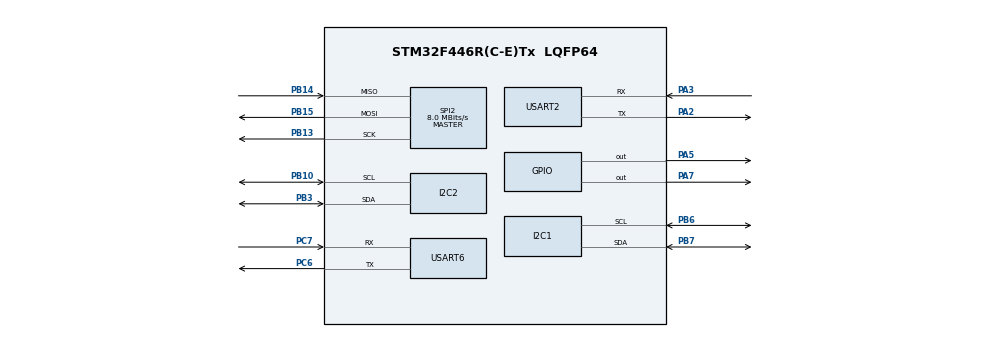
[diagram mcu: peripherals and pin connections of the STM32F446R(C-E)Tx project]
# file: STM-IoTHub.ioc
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FREERTOS.Tasks01=defaultTask,24,128,StartDefaultTask,Default,NULL,Dynamic,NULL,NULL;SensorTask,24,256,StartSensorTask,Default,NULL,Dynamic,NULL,NULL;DisplayTask,8,256,StartDisplayTask,Default,NULL,Dynamic,NULL,NULL;WiFiTask,24,256,StartWiFiTask,Default,NULL,Dynamic,NULL,NULL;RelayTask,40,256,StartRelayControlTask,Default,NULL,Dynamic,NULL,NULL;EnergyTask,24,256,StartEnergyTask,Default,NULL,Dynamic,NULL,NULL;SDLogTask,8,256,StartSDLogTask,Default,NULL,Dynamic,NULL,NULL;SystemStatusTas,8,256,StartSystemStatusTask,Default,NULL,Dynamic,NULL,NULL
Mcu.Family=STM32F4
Mcu.Name=STM32F446R(C-E)Tx
Mcu.Package=LQFP64
NVIC.PriorityGroup=NVIC_PRIORITYGROUP_4
PA2.Mode=Asynchronous
PA2.Signal=USART2_TX
PA3.Mode=Asynchronous
PA3.Signal=USART2_RX
PA5.Signal=GPIO_Output
PA7.Signal=GPIO_Output
PB10.Mode=I2C
PB10.Signal=I2C2_SCL
PB13.Mode=Full_Duplex_Master
PB13.Signal=SPI2_SCK
PB14.Mode=Full_Duplex_Master
PB14.Signal=SPI2_MISO
PB15.Mode=Full_Duplex_Master
PB15.Signal=SPI2_MOSI
PB3.Mode=I2C
PB3.Signal=I2C2_SDA
PB6.Mode=I2C
PB6.Signal=I2C1_SCL
PB7.Mode=I2C
PB7.Signal=I2C1_SDA
PC6.Mode=Asynchronous
PC6.Signal=USART6_TX
PC7.Mode=Asynchronous
PC7.Signal=USART6_RX
ProjectManager.HeapSize=0x200
ProjectManager.StackSize=0x400
ProjectManager.TargetToolchain=STM32CubeIDE
RCC.CortexFreq_Value=16000000
RCC.USBFreq_Value=96000000
RCC.VCOOutputFreq_Value=192000000
SPI2.CalculateBaudRate=8.0 MBits/s
SPI2.Direction=SPI_DIRECTION_2LINES
SPI2.Mode=SPI_MODE_MASTER
SPI2.VirtualType=VM_MASTER
USART2.VirtualMode=VM_ASYNC
USART6.VirtualMode=VM_ASYNC
VP_FATFS_VS_Generic.Mode=User_defined
VP_FREERTOS_VS_CMSIS_V2.Mode=CMSIS_V2
VP_RTC_VS_RTC_Activate.Mode=RTC_Enabled
VP_RTC_VS_RTC_Calendar.Mode=RTC_Calendar
board=custom

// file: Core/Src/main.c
/* USER CODE BEGIN Header */
/**
  ******************************************************************************
  * @file           : main.c
  * @brief          : Main program body
  ******************************************************************************
  * @attention
  *
  * Copyright (c) 2025 STMicroelectronics.
  * All rights reserved.
  *
  * This software is licensed under terms that can be found in the LICENSE file
  * in the root directory of this software component.
  * If no LICENSE file comes with this software, it is provided AS-IS.
  *
  ******************************************************************************
  */
/* USER CODE END Header */

#include "main.h"
#include "cmsis_os.h"
#include "bme68x.h"
#include "bme680_app.h"
#include "ssd1306.h"
#include "relay_control.h"
#include "pzem004t.h"
#include "esp8266.h"
#include "fatfs.h"
#include "fatfs_sd.h"

/* USER CODE BEGIN Includes */
struct bme68x_dev bme;              // Sensor device structure
struct bme68x_conf conf;            // Configuration
struct bme68x_heatr_conf heatr_conf;
extern void StartSensorTask(void *argument);
extern UART_HandleTypeDef huart2;
extern UART_HandleTypeDef huart2;
extern volatile uint8_t user_light_state;
extern osThreadId_t fanTaskHandle;
// Heater config
/* USER CODE END Includes */

I2C_HandleTypeDef hi2c1;
I2C_HandleTypeDef hi2c2;

RTC_HandleTypeDef hrtc;

SPI_HandleTypeDef hspi2;

UART_HandleTypeDef huart2;
UART_HandleTypeDef huart6;

/* Definitions for defaultTask */
osThreadId_t defaultTaskHandle;
const osThreadAttr_t defaultTask_attributes = {
  .name = "defaultTask",
  .stack_size = 128 * 4,
  .priority = (osPriority_t) osPriorityNormal,
};
/* Definitions for SensorTask */
osThreadId_t SensorTaskHandle;
const osThreadAttr_t SensorTask_attributes = {
  .name = "SensorTask",
  .stack_size = 256 * 4,
  .priority = (osPriority_t) osPriorityNormal,
};
/* Definitions for DisplayTask */
osThreadId_t DisplayTaskHandle;
const osThreadAttr_t DisplayTask_attributes = {
  .name = "DisplayTask",
  .stack_size = 256 * 4,
  .priority = (osPriority_t) osPriorityLow,
};
/* Definitions for WiFiTask */
osThreadId_t WiFiTaskHandle;
const osThreadAttr_t WiFiTask_attributes = {
  .name = "WiFiTask",
  .stack_size = 256 * 4,
  .priority = (osPriority_t) osPriorityNormal,
};
/* Definitions for RelayTask */
osThreadId_t RelayTaskHandle;
const osThreadAttr_t RelayTask_attributes = {
  .name = "RelayTask",
  .stack_size = 256 * 4,
  .priority = (osPriority_t) osPriorityHigh,
};
/* Definitions for EnergyTask */
osThreadId_t EnergyTaskHandle;
const osThreadAttr_t EnergyTask_attributes = {
  .name = "EnergyTask",
  .stack_size = 256 * 4,
  .priority = (osPriority_t) osPriorityNormal,
};
/* Definitions for SDLogTask */
osThreadId_t SDLogTaskHandle;
const osThreadAttr_t SDLogTask_attributes = {
  .name = "SDLogTask",
  .stack_size = 256 * 4,
  .priority = (osPriority_t) osPriorityLow,
};
/* Definitions for SystemStatusTas */
osThreadId_t SystemStatusTasHandle;
const osThreadAttr_t SystemStatusTas_attributes = {
  .name = "SystemStatusTas",
  .stack_size = 256 * 4,
  .priority = (osPriority_t) osPriorityLow,
};

void SystemClock_Config(void);
static void MX_GPIO_Init(void);
static void MX_I2C2_Init(void);
static void MX_USART2_UART_Init(void);
static void MX_RTC_Init(void);
static void MX_I2C1_Init(void);
static void MX_SPI2_Init(void);
static void MX_USART6_UART_Init(void);
void StartDefaultTask(void *argument);
void StartSensorTask(void *argument);
void StartDisplayTask(void *argument);
void StartWiFiTask(void *argument);
void StartRelayControlTask(void *argument);
void StartEnergyTask(void *argument);
void StartSDLogTask(void *argument);
void StartSystemStatusTask(void *argument);

int main(void)
{

  /* MCU Configuration--------------------------------------------------------*/

  /* Reset of all peripherals, Initializes the Flash interface and the Systick. */
  HAL_Init();

  /* Configure the system clock */
  SystemClock_Config();

  /* USER CODE BEGIN SysInit */
  BME680_Init();          // Initialize BME680 sensor
  SSD1306_Init();         // Initialize OLED Display
  Relay_Init();           // Initialize Relay GPIOs
  PZEM_Init(&huart2);
  ESP_Init(&huart2);
  /* USER CODE END SysInit */

  /* Initialize all configured peripherals */
  MX_GPIO_Init();
  MX_I2C2_Init();
  MX_USART2_UART_Init();
  MX_FATFS_Init();
  MX_RTC_Init();
  MX_I2C1_Init();
  MX_SPI2_Init();
  MX_USART6_UART_Init();

  /* Init scheduler */
  osKernelInitialize();

  /* Create the thread(s) */
  /* creation of defaultTask */
  defaultTaskHandle = osThreadNew(StartDefaultTask, NULL, &defaultTask_attributes);

  /* creation of SensorTask */
  SensorTaskHandle = osThreadNew(StartSensorTask, NULL, &SensorTask_attributes);

  /* creation of DisplayTask */
  DisplayTaskHandle = osThreadNew(StartDisplayTask, NULL, &DisplayTask_attributes);

  /* creation of WiFiTask */
  WiFiTaskHandle = osThreadNew(StartWiFiTask, NULL, &WiFiTask_attributes);

  /* creation of RelayTask */
  RelayTaskHandle = osThreadNew(StartRelayControlTask, NULL, &RelayTask_attributes);

  /* creation of EnergyTask */
  EnergyTaskHandle = osThreadNew(StartEnergyTask, NULL, &EnergyTask_attributes);

  /* creation of SDLogTask */
  SDLogTaskHandle = osThreadNew(StartSDLogTask, NULL, &SDLogTask_attributes);

  /* creation of SystemStatusTas */
  SystemStatusTasHandle = osThreadNew(StartSystemStatusTask, NULL, &SystemStatusTas_attributes);

  /* Start scheduler */
  osKernelStart();

  /* We should never get here as control is now taken by the scheduler */

  /* Infinite loop */
  while (1)
  {

  }
}

void SystemClock_Config(void)
{
  RCC_OscInitTypeDef RCC_OscInitStruct = {0};
  RCC_ClkInitTypeDef RCC_ClkInitStruct = {0};

  /** Configure the main internal regulator output voltage
  */
  __HAL_RCC_PWR_CLK_ENABLE();
  __HAL_PWR_VOLTAGESCALING_CONFIG(PWR_REGULATOR_VOLTAGE_SCALE3);

  /** Initializes the RCC Oscillators according to the specified parameters
  * in the RCC_OscInitTypeDef structure.
  */
  RCC_OscInitStruct.OscillatorType = RCC_OSCILLATORTYPE_HSI|RCC_OSCILLATORTYPE_LSI;
  RCC_OscInitStruct.LSEState = RCC_LSE_OFF;
  RCC_OscInitStruct.HSIState = RCC_HSI_ON;
  RCC_OscInitStruct.HSICalibrationValue = RCC_HSICALIBRATION_DEFAULT;
  RCC_OscInitStruct.LSIState = RCC_LSI_ON;
  RCC_OscInitStruct.PLL.PLLState = RCC_PLL_NONE;
  if (HAL_RCC_OscConfig(&RCC_OscInitStruct) != HAL_OK)
  {
    Error_Handler();
  }

  /** Initializes the CPU, AHB and APB buses clocks
  */
  RCC_ClkInitStruct.ClockType = RCC_CLOCKTYPE_HCLK|RCC_CLOCKTYPE_SYSCLK
                              |RCC_CLOCKTYPE_PCLK1|RCC_CLOCKTYPE_PCLK2;
  RCC_ClkInitStruct.SYSCLKSource = RCC_SYSCLKSOURCE_HSI;
  RCC_ClkInitStruct.AHBCLKDivider = RCC_SYSCLK_DIV1;
  RCC_ClkInitStruct.APB1CLKDivider = RCC_HCLK_DIV1;
  RCC_ClkInitStruct.APB2CLKDivider = RCC_HCLK_DIV1;

  if (HAL_RCC_ClockConfig(&RCC_ClkInitStruct, FLASH_LATENCY_0) != HAL_OK)
  {
    Error_Handler();
  }
}

static void MX_I2C1_Init(void)
{

  hi2c1.Instance = I2C1;
  hi2c1.Init.ClockSpeed = 100000;
  hi2c1.Init.DutyCycle = I2C_DUTYCYCLE_2;
  hi2c1.Init.OwnAddress1 = 0;
  hi2c1.Init.AddressingMode = I2C_ADDRESSINGMODE_7BIT;
  hi2c1.Init.DualAddressMode = I2C_DUALADDRESS_DISABLE;
  hi2c1.Init.OwnAddress2 = 0;
  hi2c1.Init.GeneralCallMode = I2C_GENERALCALL_DISABLE;
  hi2c1.Init.NoStretchMode = I2C_NOSTRETCH_DISABLE;
  if (HAL_I2C_Init(&hi2c1) != HAL_OK)
  {
    Error_Handler();
  }

}

static void MX_I2C2_Init(void)
{

  hi2c2.Instance = I2C2;
  hi2c2.Init.ClockSpeed = 100000;
  hi2c2.Init.DutyCycle = I2C_DUTYCYCLE_2;
  hi2c2.Init.OwnAddress1 = 0;
  hi2c2.Init.AddressingMode = I2C_ADDRESSINGMODE_7BIT;
  hi2c2.Init.DualAddressMode = I2C_DUALADDRESS_DISABLE;
  hi2c2.Init.OwnAddress2 = 0;
  hi2c2.Init.GeneralCallMode = I2C_GENERALCALL_DISABLE;
  hi2c2.Init.NoStretchMode = I2C_NOSTRETCH_DISABLE;
  if (HAL_I2C_Init(&hi2c2) != HAL_OK)
  {
    Error_Handler();
  }

}

static void MX_RTC_Init(void)
{

  RTC_TimeTypeDef sTime = {0};
  RTC_DateTypeDef sDate = {0};

  /** Initialize RTC Only
  */
  hrtc.Instance = RTC;
  hrtc.Init.HourFormat = RTC_HOURFORMAT_24;
  hrtc.Init.AsynchPrediv = 127;
  hrtc.Init.SynchPrediv = 255;
  hrtc.Init.OutPut = RTC_OUTPUT_DISABLE;
  hrtc.Init.OutPutPolarity = RTC_OUTPUT_POLARITY_HIGH;
  hrtc.Init.OutPutType = RTC_OUTPUT_TYPE_OPENDRAIN;
  if (HAL_RTC_Init(&hrtc) != HAL_OK)
  {
    Error_Handler();
  }

  /** Initialize RTC and set the Time and Date
  */
  sTime.Hours = 0x0;
  sTime.Minutes = 0x0;
  sTime.Seconds = 0x0;
  sTime.DayLightSaving = RTC_DAYLIGHTSAVING_NONE;
  sTime.StoreOperation = RTC_STOREOPERATION_RESET;
  if (HAL_RTC_SetTime(&hrtc, &sTime, RTC_FORMAT_BCD) != HAL_OK)
  {
    Error_Handler();
  }
  sDate.WeekDay = RTC_WEEKDAY_MONDAY;
  sDate.Month = RTC_MONTH_JANUARY;
  sDate.Date = 0x1;
  sDate.Year = 0x0;

  if (HAL_RTC_SetDate(&hrtc, &sDate, RTC_FORMAT_BCD) != HAL_OK)
  {
    Error_Handler();
  }

}

static void MX_SPI2_Init(void)
{

  /* SPI2 parameter configuration*/
  hspi2.Instance = SPI2;
  hspi2.Init.Mode = SPI_MODE_MASTER;
  hspi2.Init.Direction = SPI_DIRECTION_2LINES;
  hspi2.Init.DataSize = SPI_DATASIZE_8BIT;
  hspi2.Init.CLKPolarity = SPI_POLARITY_LOW;
  hspi2.Init.CLKPhase = SPI_PHASE_1EDGE;
  hspi2.Init.NSS = SPI_NSS_SOFT;
  hspi2.Init.BaudRatePrescaler = SPI_BAUDRATEPRESCALER_2;
  hspi2.Init.FirstBit = SPI_FIRSTBIT_MSB;
  hspi2.Init.TIMode = SPI_TIMODE_DISABLE;
  hspi2.Init.CRCCalculation = SPI_CRCCALCULATION_DISABLE;
  hspi2.Init.CRCPolynomial = 10;
  if (HAL_SPI_Init(&hspi2) != HAL_OK)
  {
    Error_Handler();
  }

}

static void MX_USART2_UART_Init(void)
{

  huart2.Instance = USART2;
  huart2.Init.BaudRate = 115200;
  huart2.Init.WordLength = UART_WORDLENGTH_8B;
  huart2.Init.StopBits = UART_STOPBITS_1;
  huart2.Init.Parity = UART_PARITY_NONE;
  huart2.Init.Mode = UART_MODE_TX_RX;
  huart2.Init.HwFlowCtl = UART_HWCONTROL_NONE;
  huart2.Init.OverSampling = UART_OVERSAMPLING_16;
  if (HAL_UART_Init(&huart2) != HAL_OK)
  {
    Error_Handler();
  }

}

static void MX_USART6_UART_Init(void)
{

  huart6.Instance = USART6;
  huart6.Init.BaudRate = 115200;
  huart6.Init.WordLength = UART_WORDLENGTH_8B;
  huart6.Init.StopBits = UART_STOPBITS_1;
  huart6.Init.Parity = UART_PARITY_NONE;
  huart6.Init.Mode = UART_MODE_TX_RX;
  huart6.Init.HwFlowCtl = UART_HWCONTROL_NONE;
  huart6.Init.OverSampling = UART_OVERSAMPLING_16;
  if (HAL_UART_Init(&huart6) != HAL_OK)
  {
    Error_Handler();
  }

}

static void MX_GPIO_Init(void)
{
  GPIO_InitTypeDef GPIO_InitStruct = {0};

  /* GPIO Ports Clock Enable */
  __HAL_RCC_GPIOA_CLK_ENABLE();
  __HAL_RCC_GPIOB_CLK_ENABLE();
  __HAL_RCC_GPIOC_CLK_ENABLE();

  /*Configure GPIO pin Output Level */
  HAL_GPIO_WritePin(GPIOA, GPIO_PIN_5|GPIO_PIN_7, GPIO_PIN_RESET);

  /*Configure GPIO pins : PA5 PA7 */
  GPIO_InitStruct.Pin = GPIO_PIN_5|GPIO_PIN_7;
  GPIO_InitStruct.Mode = GPIO_MODE_OUTPUT_PP;
  GPIO_InitStruct.Pull = GPIO_NOPULL;
  GPIO_InitStruct.Speed = GPIO_SPEED_FREQ_LOW;
  HAL_GPIO_Init(GPIOA, &GPIO_InitStruct);

}

void StartDefaultTask(void *argument)
{
  for(;;)
  {
    osDelay(1);
  }
}

void StartDisplayTask(void *argument)
{
  for(;;)
  {
    osDelay(1);
  }
}

void StartWiFiTask(void *argument)
{
  for(;;)
  {
    osDelay(1);
  }
}

void StartRelayControlTask(void *argument)
{
  for(;;)
  {
    osDelay(1);
  }
}

void StartSDLogTask(void *argument)
{
  for(;;)
  {
    osDelay(1);
  }
}

void StartSystemStatusTask(void *argument)
{
  for(;;)
  {
    osDelay(1);
  }
}

void Error_Handler(void)
{
  __disable_irq();
  while (1)
  {
  }
}
